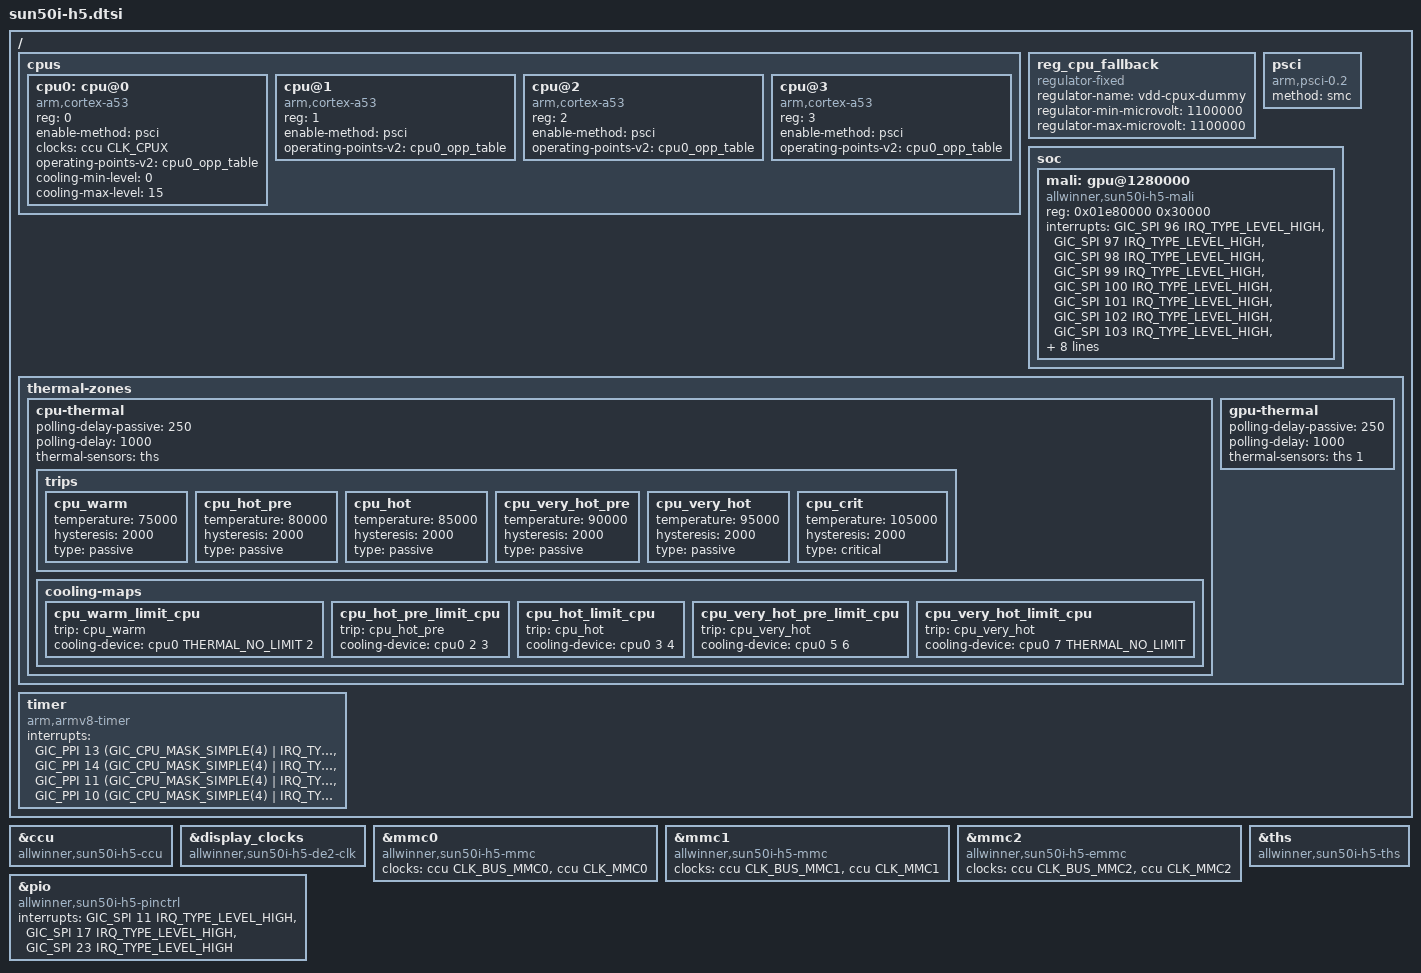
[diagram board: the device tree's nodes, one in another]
/*
 * Copyright (C) 2016 ARM Ltd.
 *
 * This file is dual-licensed: you can use it either under the terms
 * of the GPL or the X11 license, at your option. Note that this dual
 * licensing only applies to this file, and not this project as a
 * whole.
 *
 *  a) This file is free software; you can redistribute it and/or
 *     modify it under the terms of the GNU General Public License as
 *     published by the Free Software Foundation; either version 2 of the
 *     License, or (at your option) any later version.
 *
 *     This file is distributed in the hope that it will be useful,
 *     but WITHOUT ANY WARRANTY; without even the implied warranty of
 *     MERCHANTABILITY or FITNESS FOR A PARTICULAR PURPOSE.  See the
 *     GNU General Public License for more details.
 *
 * Or, alternatively,
 *
 *  b) Permission is hereby granted, free of charge, to any person
 *     obtaining a copy of this software and associated documentation
 *     files (the "Software"), to deal in the Software without
 *     restriction, including without limitation the rights to use,
 *     copy, modify, merge, publish, distribute, sublicense, and/or
 *     sell copies of the Software, and to permit persons to whom the
 *     Software is furnished to do so, subject to the following
 *     conditions:
 *
 *     The above copyright notice and this permission notice shall be
 *     included in all copies or substantial portions of the Software.
 *
 *     THE SOFTWARE IS PROVIDED "AS IS", WITHOUT WARRANTY OF ANY KIND,
 *     EXPRESS OR IMPLIED, INCLUDING BUT NOT LIMITED TO THE WARRANTIES
 *     OF MERCHANTABILITY, FITNESS FOR A PARTICULAR PURPOSE AND
 *     NONINFRINGEMENT. IN NO EVENT SHALL THE AUTHORS OR COPYRIGHT
 *     HOLDERS BE LIABLE FOR ANY CLAIM, DAMAGES OR OTHER LIABILITY,
 *     WHETHER IN AN ACTION OF CONTRACT, TORT OR OTHERWISE, ARISING
 *     FROM, OUT OF OR IN CONNECTION WITH THE SOFTWARE OR THE USE OR
 *     OTHER DEALINGS IN THE SOFTWARE.
 */

#include <arm/sunxi-h3-h5.dtsi>
#include <dt-bindings/thermal/thermal.h>

/ {
	cpus {
		#address-cells = <1>;
		#size-cells = <0>;

		cpu0: cpu@0 {
			compatible = "arm,cortex-a53", "arm,armv8";
			device_type = "cpu";
			reg = <0>;
			enable-method = "psci";
			clocks = <&ccu CLK_CPUX>;
			clock-names = "cpu";
			operating-points-v2 = <&cpu0_opp_table>;
			#cooling-cells = <2>;
			cooling-min-level = <0>;
			cooling-max-level = <15>;
		};

		cpu@1 {
			compatible = "arm,cortex-a53", "arm,armv8";
			device_type = "cpu";
			reg = <1>;
			enable-method = "psci";
			operating-points-v2 = <&cpu0_opp_table>;
		};

		cpu@2 {
			compatible = "arm,cortex-a53", "arm,armv8";
			device_type = "cpu";
			reg = <2>;
			enable-method = "psci";
			operating-points-v2 = <&cpu0_opp_table>;
		};

		cpu@3 {
			compatible = "arm,cortex-a53", "arm,armv8";
			device_type = "cpu";
			reg = <3>;
			enable-method = "psci";
			operating-points-v2 = <&cpu0_opp_table>;
		};
	};

	reg_cpu_fallback: reg_cpu_fallback  {
		compatible = "regulator-fixed";
		regulator-name = "vdd-cpux-dummy";
		regulator-min-microvolt = <1100000>;
		regulator-max-microvolt = <1100000>;
	};

	psci {
		compatible = "arm,psci-0.2";
		method = "smc";
	};

	soc {
		mali: gpu@1280000 {
			compatible = "allwinner,sun50i-h5-mali",
				     "arm,mali-450";
			reg = <0x01e80000 0x30000>;
			interrupts = <GIC_SPI 96 IRQ_TYPE_LEVEL_HIGH>,
				     <GIC_SPI 97 IRQ_TYPE_LEVEL_HIGH>,
				     <GIC_SPI 98 IRQ_TYPE_LEVEL_HIGH>,
				     <GIC_SPI 99 IRQ_TYPE_LEVEL_HIGH>,
				     <GIC_SPI 100 IRQ_TYPE_LEVEL_HIGH>,
				     <GIC_SPI 101 IRQ_TYPE_LEVEL_HIGH>,
				     <GIC_SPI 102 IRQ_TYPE_LEVEL_HIGH>,
				     <GIC_SPI 103 IRQ_TYPE_LEVEL_HIGH>,
				     <GIC_SPI 104 IRQ_TYPE_LEVEL_HIGH>,
				     <GIC_SPI 105 IRQ_TYPE_LEVEL_HIGH>,
				     <GIC_SPI 106 IRQ_TYPE_LEVEL_HIGH>,
				     <GIC_SPI 107 IRQ_TYPE_LEVEL_HIGH>;
			interrupt-names = "gp",
					  "gpmmu",
					  "pmu",
					  "pp",
					  "pp0",
					  "ppmmu0",
					  "pp1",
					  "ppmmu1",
					  "pp2",
					  "ppmmu2",
					  "pp3",
					  "ppmmu3";
			clocks = <&ccu CLK_BUS_GPU>, <&ccu CLK_GPU>;
			clock-names = "bus", "core";
			resets = <&ccu RST_BUS_GPU>;

			assigned-clocks = <&ccu CLK_GPU>;
			assigned-clock-rates = <384000000>;
		};
	};

	thermal-zones {
		cpu-thermal {
			/* milliseconds */
			polling-delay-passive = <250>;
			polling-delay = <1000>;
			thermal-sensors = <&ths 0>;
		};

		gpu-thermal {
			/* milliseconds */
			polling-delay-passive = <250>;
			polling-delay = <1000>;
			thermal-sensors = <&ths 1>;
		};
	};

	thermal-zones {
		cpu-thermal {
			/* milliseconds */
			polling-delay-passive = <250>;
			polling-delay = <1000>;
			thermal-sensors = <&ths>;

			trips {
				cpu_warm: cpu_warm {
					temperature = <75000>;
					hysteresis = <2000>;
					type = "passive";
				};

				cpu_hot_pre: cpu_hot_pre {
					temperature = <80000>;
					hysteresis = <2000>;
					type = "passive";
				};

				cpu_hot: cpu_hot {
					temperature = <85000>;
					hysteresis = <2000>;
					type = "passive";
				};

				cpu_very_hot_pre: cpu_very_hot_pre {
					temperature = <90000>;
					hysteresis = <2000>;
					type = "passive";
				};

				cpu_very_hot: cpu_very_hot {
					temperature = <95000>;
					hysteresis = <2000>;
					type = "passive";
				};

				cpu_crit: cpu_crit {
					temperature = <105000>;
					hysteresis = <2000>;
					type = "critical";
				};
			};

			cooling-maps {
				cpu_warm_limit_cpu {
					trip = <&cpu_warm>;
					cooling-device = <&cpu0 THERMAL_NO_LIMIT 2>;
				};

				cpu_hot_pre_limit_cpu {
					trip = <&cpu_hot_pre>;
					cooling-device = <&cpu0 2 3>;
				};

				cpu_hot_limit_cpu {
					trip = <&cpu_hot>;
					cooling-device = <&cpu0 3 4>;
				};

				cpu_very_hot_pre_limit_cpu {
					trip = <&cpu_very_hot>;
					cooling-device = <&cpu0 5 6>;
				};

				cpu_very_hot_limit_cpu {
					trip = <&cpu_very_hot>;
					cooling-device = <&cpu0 7 THERMAL_NO_LIMIT>;
				};
			};
		};
	};

	timer {
		compatible = "arm,armv8-timer";
		interrupts = <GIC_PPI 13
				(GIC_CPU_MASK_SIMPLE(4) | IRQ_TYPE_LEVEL_LOW)>,
			     <GIC_PPI 14
				(GIC_CPU_MASK_SIMPLE(4) | IRQ_TYPE_LEVEL_LOW)>,
			     <GIC_PPI 11
				(GIC_CPU_MASK_SIMPLE(4) | IRQ_TYPE_LEVEL_LOW)>,
			     <GIC_PPI 10
				(GIC_CPU_MASK_SIMPLE(4) | IRQ_TYPE_LEVEL_LOW)>;
	};
};

&ccu {
	compatible = "allwinner,sun50i-h5-ccu";
};

&display_clocks {
	compatible = "allwinner,sun50i-h5-de2-clk";
};

&mmc0 {
	compatible = "allwinner,sun50i-h5-mmc",
		     "allwinner,sun50i-a64-mmc";
	clocks = <&ccu CLK_BUS_MMC0>, <&ccu CLK_MMC0>;
	clock-names = "ahb", "mmc";
};

&mmc1 {
	compatible = "allwinner,sun50i-h5-mmc",
		     "allwinner,sun50i-a64-mmc";
	clocks = <&ccu CLK_BUS_MMC1>, <&ccu CLK_MMC1>;
	clock-names = "ahb", "mmc";
};

&mmc2 {
	compatible = "allwinner,sun50i-h5-emmc",
		     "allwinner,sun50i-a64-emmc";
	clocks = <&ccu CLK_BUS_MMC2>, <&ccu CLK_MMC2>;
	clock-names = "ahb", "mmc";
};

&pio {
	interrupts = <GIC_SPI 11 IRQ_TYPE_LEVEL_HIGH>,
		     <GIC_SPI 17 IRQ_TYPE_LEVEL_HIGH>,
		     <GIC_SPI 23 IRQ_TYPE_LEVEL_HIGH>;
	compatible = "allwinner,sun50i-h5-pinctrl";
};

&ths {
	compatible = "allwinner,sun50i-h5-ths";
	#thermal-sensor-cells = <1>;
};
